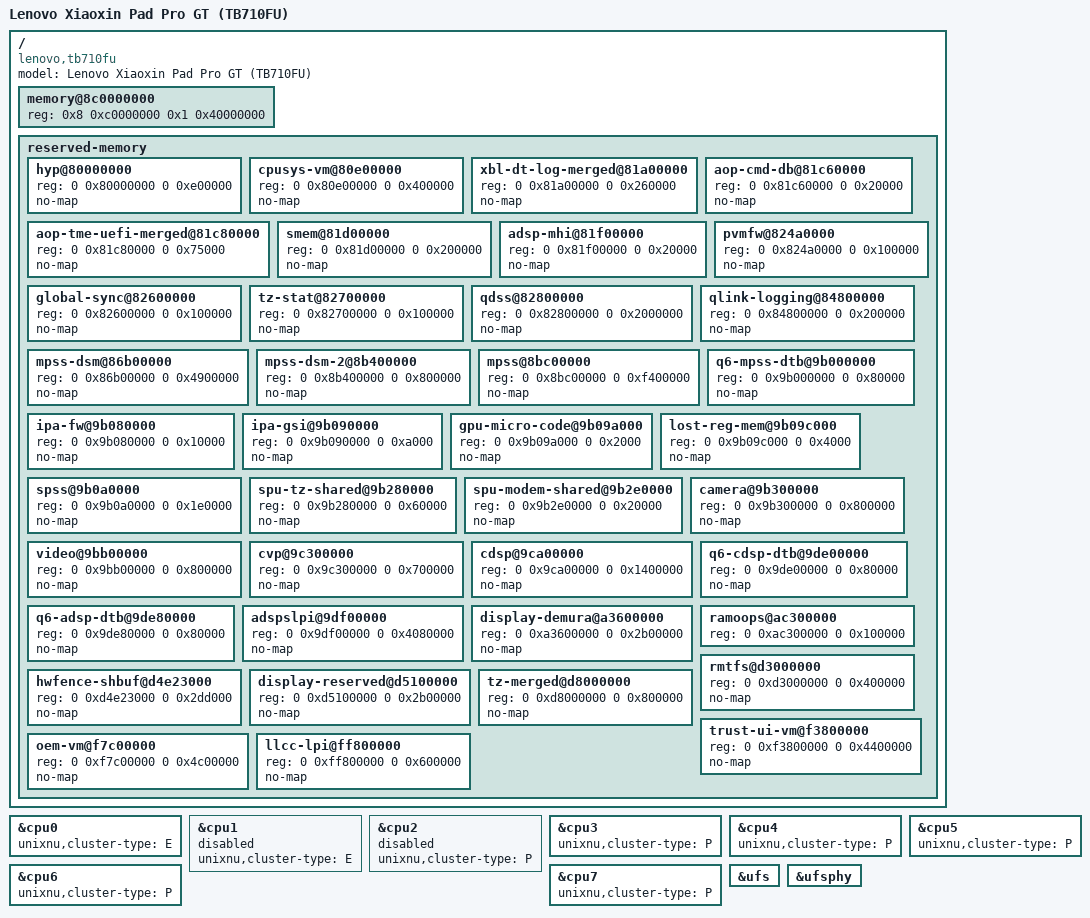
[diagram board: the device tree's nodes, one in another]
// SPDX-License-Identifier: BSD-3-Clause
// Lenovo Xiaoxin Pad Pro GT (TB710FU) board device tree for UniXNU.
// GENERATED by scripts/gen-board-dts.py from the mainline Linux DTB
// (sm8650-lenovo-tb710fu.dtb). Do not edit the reserved-memory block by hand.
/dts-v1/;
/include/ "sm8650.dtsi"

/ {
    model = "Lenovo Xiaoxin Pad Pro GT (TB710FU)";
    compatible = "lenovo,tb710fu", "qcom,sm8650";

    // Largest contiguous DDR run of the live device tree (8 GB SKU: 2 GiB low bank,
    // 6 GiB high bank with secure holes). DarwinBoot allocates the owned window inside it.
    memory@8c0000000 {
        device_type = "memory";
        reg = <0x8 0xc0000000 0x1 0x40000000>;
    };

    reserved-memory {
        #address-cells = <2>;
        #size-cells = <2>;
        ranges;

        hyp@80000000 { reg = <0 0x80000000 0 0xe00000>; no-map; };
        cpusys-vm@80e00000 { reg = <0 0x80e00000 0 0x400000>; no-map; };
        xbl-dt-log-merged@81a00000 { reg = <0 0x81a00000 0 0x260000>; no-map; };
        aop-cmd-db@81c60000 { reg = <0 0x81c60000 0 0x20000>; no-map; };
        aop-tme-uefi-merged@81c80000 { reg = <0 0x81c80000 0 0x75000>; no-map; };
        smem@81d00000 { reg = <0 0x81d00000 0 0x200000>; no-map; };
        adsp-mhi@81f00000 { reg = <0 0x81f00000 0 0x20000>; no-map; };
        pvmfw@824a0000 { reg = <0 0x824a0000 0 0x100000>; no-map; };
        global-sync@82600000 { reg = <0 0x82600000 0 0x100000>; no-map; };
        tz-stat@82700000 { reg = <0 0x82700000 0 0x100000>; no-map; };
        qdss@82800000 { reg = <0 0x82800000 0 0x2000000>; no-map; };
        qlink-logging@84800000 { reg = <0 0x84800000 0 0x200000>; no-map; };
        mpss-dsm@86b00000 { reg = <0 0x86b00000 0 0x4900000>; no-map; };
        mpss-dsm-2@8b400000 { reg = <0 0x8b400000 0 0x800000>; no-map; };
        mpss@8bc00000 { reg = <0 0x8bc00000 0 0xf400000>; no-map; };
        q6-mpss-dtb@9b000000 { reg = <0 0x9b000000 0 0x80000>; no-map; };
        ipa-fw@9b080000 { reg = <0 0x9b080000 0 0x10000>; no-map; };
        ipa-gsi@9b090000 { reg = <0 0x9b090000 0 0xa000>; no-map; };
        gpu-micro-code@9b09a000 { reg = <0 0x9b09a000 0 0x2000>; no-map; };
        lost-reg-mem@9b09c000 { reg = <0 0x9b09c000 0 0x4000>; no-map; };
        spss@9b0a0000 { reg = <0 0x9b0a0000 0 0x1e0000>; no-map; };
        spu-tz-shared@9b280000 { reg = <0 0x9b280000 0 0x60000>; no-map; };
        spu-modem-shared@9b2e0000 { reg = <0 0x9b2e0000 0 0x20000>; no-map; };
        camera@9b300000 { reg = <0 0x9b300000 0 0x800000>; no-map; };
        video@9bb00000 { reg = <0 0x9bb00000 0 0x800000>; no-map; };
        cvp@9c300000 { reg = <0 0x9c300000 0 0x700000>; no-map; };
        cdsp@9ca00000 { reg = <0 0x9ca00000 0 0x1400000>; no-map; };
        q6-cdsp-dtb@9de00000 { reg = <0 0x9de00000 0 0x80000>; no-map; };
        q6-adsp-dtb@9de80000 { reg = <0 0x9de80000 0 0x80000>; no-map; };
        adspslpi@9df00000 { reg = <0 0x9df00000 0 0x4080000>; no-map; };
        display-demura@a3600000 { reg = <0 0xa3600000 0 0x2b00000>; no-map; };
        ramoops@ac300000 { reg = <0 0xac300000 0 0x100000>; };
        rmtfs@d3000000 { reg = <0 0xd3000000 0 0x400000>; no-map; };
        hwfence-shbuf@d4e23000 { reg = <0 0xd4e23000 0 0x2dd000>; no-map; };
        display-reserved@d5100000 { reg = <0 0xd5100000 0 0x2b00000>; no-map; };
        tz-merged@d8000000 { reg = <0 0xd8000000 0 0x800000>; no-map; };
        trust-ui-vm@f3800000 { reg = <0 0xf3800000 0 0x4400000>; no-map; };
        oem-vm@f7c00000 { reg = <0 0xf7c00000 0 0x4c00000>; no-map; };
        llcc-lpi@ff800000 { reg = <0 0xff800000 0 0x600000>; no-map; };
    };
};

// SM8650 CPU topology: 2x A520 (E), 5x A720 (P), 1x X4 (P) -- see sm8650.dtsi.
// TB710FU carries a cut SM8650: the live FDT marks cpu@100 (A520) and cpu@200 (A720)
// status = "fail", so XNU gets 6 CPUs (1 E + 5 P).
&cpu0 { unixnu,cluster-type = "E"; };
&cpu1 { unixnu,cluster-type = "E"; status = "disabled"; };
&cpu2 { unixnu,cluster-type = "P"; status = "disabled"; };
&cpu3 { unixnu,cluster-type = "P"; };
&cpu4 { unixnu,cluster-type = "P"; };
&cpu5 { unixnu,cluster-type = "P"; };
&cpu6 { unixnu,cluster-type = "P"; };
&cpu7 { unixnu,cluster-type = "P"; };
&ufs { status = "okay"; };
&ufsphy { status = "okay"; };
